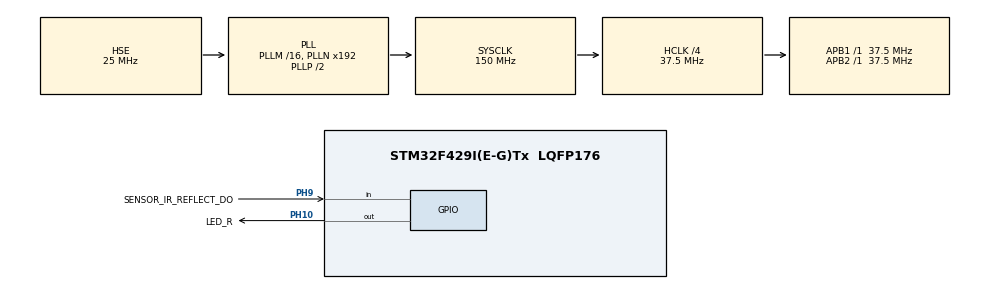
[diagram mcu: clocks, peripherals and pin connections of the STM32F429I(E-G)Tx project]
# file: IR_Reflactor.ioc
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Mcu.Family=STM32F4
Mcu.Name=STM32F429I(E-G)Tx
Mcu.Package=LQFP176
NVIC.PriorityGroup=NVIC_PRIORITYGROUP_4
PA13.Mode=Serial_Wire
PA13.Signal=SYS_JTMS-SWDIO
PA14.Mode=Serial_Wire
PA14.Signal=SYS_JTCK-SWCLK
PC14/OSC32_IN.Mode=LSE-External-Oscillator
PC14/OSC32_IN.Signal=RCC_OSC32_IN
PC15/OSC32_OUT.Mode=LSE-External-Oscillator
PC15/OSC32_OUT.Signal=RCC_OSC32_OUT
PH0/OSC_IN.Mode=HSE-External-Oscillator
PH0/OSC_IN.Signal=RCC_OSC_IN
PH1/OSC_OUT.Mode=HSE-External-Oscillator
PH1/OSC_OUT.Signal=RCC_OSC_OUT
PH10.GPIO_Label=LED_R
PH10.PinState=GPIO_PIN_SET
PH10.Signal=GPIO_Output
PH9.GPIO_Label=SENSOR_IR_REFLECT_DO
PH9.GPIO_PuPd=GPIO_PULLUP
PH9.Signal=GPIO_Input
ProjectManager.HeapSize=0x200
ProjectManager.StackSize=0x400
ProjectManager.TargetToolchain=MDK-ARM V5.32
RCC.48MHZClocksFreq_Value=75000000
RCC.AHBCLKDivider=RCC_SYSCLK_DIV4
RCC.AHBFreq_Value=37500000
RCC.APB1Freq_Value=37500000
RCC.APB1TimFreq_Value=37500000
RCC.APB2Freq_Value=37500000
RCC.APB2TimFreq_Value=37500000
RCC.CortexFreq_Value=37500000
RCC.HCLKFreq_Value=37500000
RCC.HSE_VALUE=25000000
RCC.HSI_VALUE=16000000
RCC.PLLSourceVirtual=RCC_PLLSOURCE_HSE
RCC.SYSCLKFreq_VALUE=150000000
RCC.SYSCLKSource=RCC_SYSCLKSOURCE_PLLCLK
RCC.VCOOutputFreq_Value=300000000
board=custom

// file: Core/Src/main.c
/* USER CODE BEGIN Header */
/**
  ******************************************************************************
  * @file           : main.c
  * @brief          : Main program body
  ******************************************************************************
  * @attention
  *
  * Copyright (c) 2026 STMicroelectronics.
  * All rights reserved.
  *
  * This software is licensed under terms that can be found in the LICENSE file
  * in the root directory of this software component.
  * If no LICENSE file comes with this software, it is provided AS-IS.
  *
  ******************************************************************************
  */
/* USER CODE END Header */
#include "main.h"
#include "gpio.h"

void SystemClock_Config(void);

int main(void)
{

  /* MCU Configuration--------------------------------------------------------*/

  /* Reset of all peripherals, Initializes the Flash interface and the Systick. */
  HAL_Init();

  /* Configure the system clock */
  SystemClock_Config();

  /* Initialize all configured peripherals */
  MX_GPIO_Init();

  /* Infinite loop */
  /* USER CODE BEGIN WHILE */
  while (1)
  {
		// When IR reflactor's DO output low level, means the light intensity is over the threshold
		if (HAL_GPIO_ReadPin(GPIOH, SENSOR_IR_REFLECT_DO_Pin) == GPIO_PIN_RESET)
		{
			// Enable LED
			HAL_GPIO_WritePin(GPIOH, LED_R_Pin, GPIO_PIN_RESET);
		} else {
			// Dim LED
			HAL_GPIO_WritePin(GPIOH, LED_R_Pin, GPIO_PIN_SET);
		}

    /* USER CODE END WHILE */

  }
}

void SystemClock_Config(void)
{
  RCC_OscInitTypeDef RCC_OscInitStruct = {0};
  RCC_ClkInitTypeDef RCC_ClkInitStruct = {0};

  /** Configure the main internal regulator output voltage
  */
  __HAL_RCC_PWR_CLK_ENABLE();
  __HAL_PWR_VOLTAGESCALING_CONFIG(PWR_REGULATOR_VOLTAGE_SCALE3);

  /** Initializes the RCC Oscillators according to the specified parameters
  * in the RCC_OscInitTypeDef structure.
  */
  RCC_OscInitStruct.OscillatorType = RCC_OSCILLATORTYPE_HSE;
  RCC_OscInitStruct.HSEState = RCC_HSE_ON;
  RCC_OscInitStruct.PLL.PLLState = RCC_PLL_ON;
  RCC_OscInitStruct.PLL.PLLSource = RCC_PLLSOURCE_HSE;
  RCC_OscInitStruct.PLL.PLLM = 16;
  RCC_OscInitStruct.PLL.PLLN = 192;
  RCC_OscInitStruct.PLL.PLLP = RCC_PLLP_DIV2;
  RCC_OscInitStruct.PLL.PLLQ = 4;
  if (HAL_RCC_OscConfig(&RCC_OscInitStruct) != HAL_OK)
  {
    Error_Handler();
  }

  /** Initializes the CPU, AHB and APB buses clocks
  */
  RCC_ClkInitStruct.ClockType = RCC_CLOCKTYPE_HCLK|RCC_CLOCKTYPE_SYSCLK
                              |RCC_CLOCKTYPE_PCLK1|RCC_CLOCKTYPE_PCLK2;
  RCC_ClkInitStruct.SYSCLKSource = RCC_SYSCLKSOURCE_PLLCLK;
  RCC_ClkInitStruct.AHBCLKDivider = RCC_SYSCLK_DIV4;
  RCC_ClkInitStruct.APB1CLKDivider = RCC_HCLK_DIV1;
  RCC_ClkInitStruct.APB2CLKDivider = RCC_HCLK_DIV1;

  if (HAL_RCC_ClockConfig(&RCC_ClkInitStruct, FLASH_LATENCY_1) != HAL_OK)
  {
    Error_Handler();
  }
}

void Error_Handler(void)
{
  __disable_irq();
  while (1)
  {
  }
}
